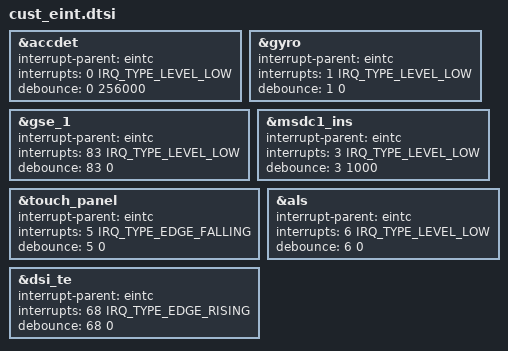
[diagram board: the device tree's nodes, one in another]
/*
 * Generated by MTK SP Drv_CodeGen Version 03.13.6	for MT6580. Copyright MediaTek Inc. (C) 2013.
 * Mon Feb 26 21:57:48 2024
 * Do Not Modify the File.
 */

#include <dt-bindings/interrupt-controller/irq.h>
#include <dt-bindings/interrupt-controller/arm-gic.h>

/*************************
 * EINT DTSI File
*************************/

&accdet {
	interrupt-parent = <&eintc>;
	interrupts = <0 IRQ_TYPE_LEVEL_LOW>;
	debounce = <0 256000>;
	status = "okay";
};
&gyro {
	interrupt-parent = <&eintc>;
	interrupts = <1 IRQ_TYPE_LEVEL_LOW>;
	debounce = <1 0>;
	status = "okay";
};
&gse_1 {
	interrupt-parent = <&eintc>;
	interrupts = <83 IRQ_TYPE_LEVEL_LOW>;
	debounce = <83 0>;
	status = "okay";
};
&msdc1_ins {
	interrupt-parent = <&eintc>;
	interrupts = <3 IRQ_TYPE_LEVEL_LOW>;
	debounce = <3 1000>;
	status = "okay";
};
&touch_panel {
	interrupt-parent = <&eintc>;
	interrupts = <5 IRQ_TYPE_EDGE_FALLING>;
	debounce = <5 0>;
	status = "okay";
};
&als {
	interrupt-parent = <&eintc>;
	interrupts = <6 IRQ_TYPE_LEVEL_LOW>;
	debounce = <6 0>;
	status = "okay";
};
&dsi_te {
	interrupt-parent = <&eintc>;
	interrupts = <68 IRQ_TYPE_EDGE_RISING>;
	debounce = <68 0>;
	status = "okay";
};
